# STM32F373 register map
File version: 1.7
CPU: CM4 r1p0, little endian, MPU, FPU, 4 interrupt priority bits
Registers are 32-bit, read-write, reset 0x0 unless marked. A register's access mark holds for its fields unless they carry their own. Offsets are from the block's base; [hi:lo] are bit positions; <NAME> marks a mode.

## CRC — cyclic redundancy check calculation unit
Base 0x40023000
0x00 DR reset 0xFFFFFFFF — Data register
  [31:0] DR — Data register bits
0x00 DR8 8-bit reset 0xFF (alternate view of DR) — Data register - byte sized
  [7:0] DR8 — Data register bits
0x00 DR16 16-bit reset 0xFFFF (alternate view of DR) — Data register - half-word sized
  [15:0] DR16 — Data register bits
0x04 IDR — Independent data register
  [7:0] IDR — General-purpose 8-bit data register bits
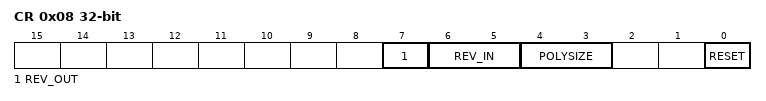
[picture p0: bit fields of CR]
0x08 CR — Control register
  [7] REV_OUT — Reverse output data
    0=Normal (Bit order not affected); 1=Reversed (Bit reversed output)
  [6:5] REV_IN — Reverse input data
    0=Normal (Bit order not affected); 1=Byte (Bit reversal done by byte); 2=HalfWord (Bit reversal done by half-word); 3=Word (Bit reversal done by word)
  [4:3] POLYSIZE — Polynomial size
    0=32-bit polynomial; 1=16-bit polynomial; 2=8-bit polynomial; 3=7-bit polynomial
  [0] RESET — reset bit
    on write: 1=Resets the CRC calculation unit and sets the data register to 0xFFFF FFFF
0x10 INIT reset 0xFFFFFFFF — Initial CRC value
  [31:0] INIT — Programmable initial CRC value
0x14 POL reset 0x4C11DB7 — CRC polynomial
  [31:0] POL — Programmable polynomial

## FLASH
Base 0x40022000
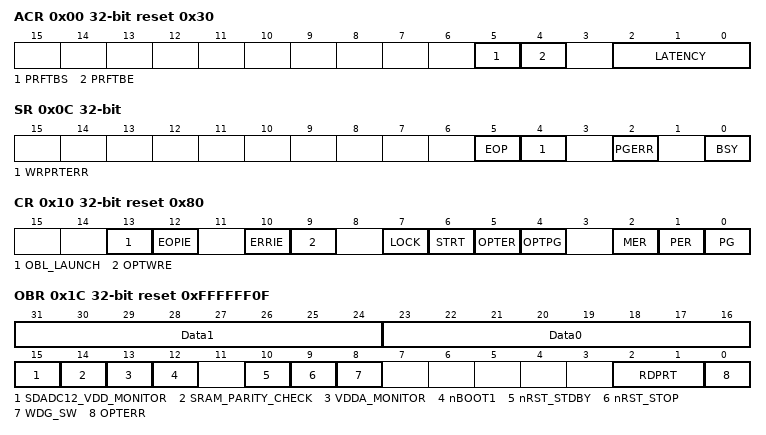
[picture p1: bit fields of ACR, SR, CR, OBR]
0x00 ACR access per field reset 0x30 — Flash access control register
  [5] PRFTBS ro
    0=Disabled (Prefetch buffer is disabled); 1=Enabled (Prefetch buffer is enabled)
  [4] PRFTBE rw
    0=Disabled (Prefetch is disabled); 1=Enabled (Prefetch is enabled)
  [2:0] LATENCY rw
    0=WS0 (0 wait states, if 0 < HCLK <= 24 MHz); 1=WS1 (1 wait state, if 24 < HCLK <= 48 MHz); 2=WS2 (2 wait states, if 48 < HCLK <= 72 MHz)
0x04 KEYR wo — Flash key register
  [31:0] FKEYR — Flash Key
0x08 OPTKEYR wo — Flash option key register
  [31:0] OPTKEYR — Option byte key
0x0C SR access per field — Flash status register
  [5] EOP rw — End of operation
    on read: 0=NoEvent (No EOP event occurred); 1=Event (An EOP event occurred) | on write: 1=Reset EOP event
  [4] WRPRTERR rw — Write protection error
    on read: 0=NoError (No write protection error occurred); 1=Error (A write protection error occurred) | on write: 1=Reset write protection error
  [2] PGERR rw — Programming error
    on read: 0=NoError (No programming error occurred); 1=Error (A programming error occurred) | on write: 1=Reset programming error
  [0] BSY ro — Busy
    0=Inactive (No write/erase operation is in progress); 1=Active (No write/erase operation is in progress)
0x10 CR reset 0x80 — Flash control register
  [13] OBL_LAUNCH — Force option byte loading
    0=Inactive (Force option byte loading inactive); 1=Active (Force option byte loading active)
  [12] EOPIE — End of operation interrupt enable
    0=Disabled (End of operation interrupt disabled); 1=Enabled (End of operation interrupt enabled)
  [10] ERRIE — Error interrupt enable
    0=Disabled (Error interrupt generation disabled); 1=Enabled (Error interrupt generation enabled)
  [9] OPTWRE — Option bytes write enable
    0=Disabled (Option byte write enabled); 1=Enabled (Option byte write disabled)
  [7] LOCK
    on read: 0=Unlocked (FLASH_CR register is unlocked); 1=Locked (FLASH_CR register is locked) | on write: 1=Lock the FLASH_CR register
  [6] STRT — Start
    1=Start (Trigger an erase operation)
  [5] OPTER — Option byte erase
    1=OptionByteErase (Erase option byte activated)
  [4] OPTPG — Option byte programming
    1=OptionByteProgramming (Program option byte activated)
  [2] MER — Mass erase
    1=MassErase (Erase activated for all user sectors)
  [1] PER — Page erase
    1=PageErase (Erase activated for selected page)
  [0] PG — Programming
    1=Program (Flash programming activated)
0x14 AR wo — Flash address register
  [31:0] FAR — Flash address
0x1C OBR ro reset 0xFFFFFF0F — Option byte register
  [31:24] Data1
  [23:16] Data0
  [15] SDADC12_VDD_MONITOR
    0=Disabled (VDDSD12 monitoring disabled); 1=Enabled (VDDSD12 monitoring enabled)
  [14] SRAM_PARITY_CHECK
    0=Disabled (RAM parity check disabled); 1=Enabled (RAM parity check enabled)
  [13] VDDA_MONITOR
    0=Disabled (VDDA power supply supervisor disabled); 1=Enabled (VDDA power supply supervisor enabled)
  [12] nBOOT1 — BOOT1
    0=Disabled (Together with BOOT0, select the device boot mode); 1=Enabled (Together with BOOT0, select the device boot mode)
  [10] nRST_STDBY
    0=Reset generated when entering Standby mode; 1=No reset generated
  [9] nRST_STOP
    0=Reset generated when entering Stop mode; 1=No reset generated
  [8] WDG_SW
    0=Hardware watchdog; 1=Software watchdog
  [2:1] RDPRT — Read protection Level status
    0=Level0; 1=Level1; 3=Level2
  [0] OPTERR — Option byte error
    1=OptionByteError (The loaded option byte and its complement do not match)
0x20 WRPR ro reset 0xFFFFFFFF — Write protection register
  [31:0] WRP — Write protect
